# UPD70F3508 register map
Vendor: Renesas; Series: V850E2/Px4; File version: 1.0
CPU: other r0p0, little endian, no MPU, FPU, 4 interrupt priority bits
Registers are 8-bit, read-write, reset 0x0 unless marked. A register's access mark holds for its fields unless they carry their own. Offsets are from the block's base; [hi:lo] are bit positions; {n}, {i} and the like mark numbered series.

## FLX0 — FlexRay controller 0 (E-Ray)
Base 0xFF580000
0x00 FLX0CI 32-bit ro reset 0x65726179 — Controller information
  [31:0] FLX0MN — Controller information (ASCII eray)
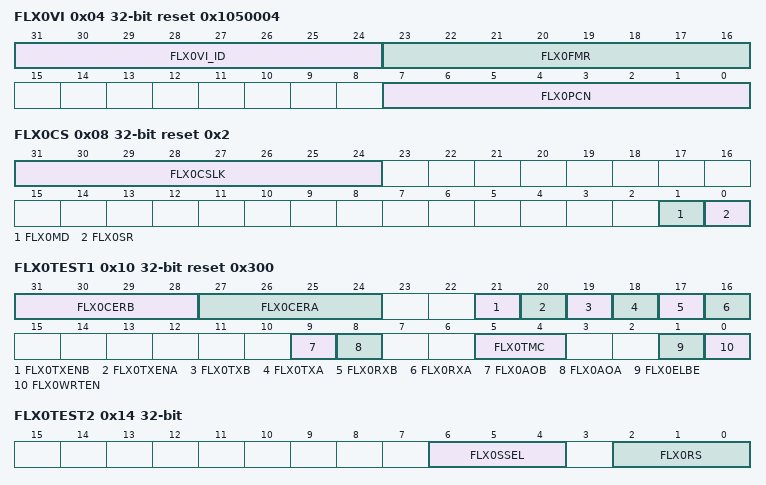
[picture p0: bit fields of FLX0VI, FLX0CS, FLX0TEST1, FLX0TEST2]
0x04 FLX0VI 32-bit ro reset 0x1050004 — Vendor information
  [31:24] FLX0VI_ID — Vendor ID
  [23:16] FLX0FMR — FlexRay controller release number
  [7:0] FLX0PCN — Product code number
0x08 FLX0CS 32-bit reset 0x2 — Control setting
  [31:24] FLX0CSLK — Control setting lock key
  [1] FLX0MD — Controller disable
  [0] FLX0SR — Software reset
0x10 FLX0TEST1 32-bit reset 0x300 — Test register 1
  [31:28] FLX0CERB — Coding error report channel B
  [27:24] FLX0CERA — Coding error report channel A
  [21] FLX0TXENB — Control of channel B transmit enable signal
  [20] FLX0TXENA — Control of channel A transmit enable signal
  [19] FLX0TXB — Control of channel B transmit signal
  [18] FLX0TXA — Control of channel A transmit signal
  [17] FLX0RXB — Monitor channel B receive signal
  [16] FLX0RXA — Monitor channel A receive signal
  [9] FLX0AOB — Activity detected on channel B
  [8] FLX0AOA — Activity detected on channel A
  [5:4] FLX0TMC — Test multiplexer control
  [1] FLX0ELBE — External loop back enable
  [0] FLX0WRTEN — Write test register enable
0x14 FLX0TEST2 32-bit — Test register 2
  [6:4] FLX0SSEL — RAM segment setting
  [2:0] FLX0RS — RAM selection setting
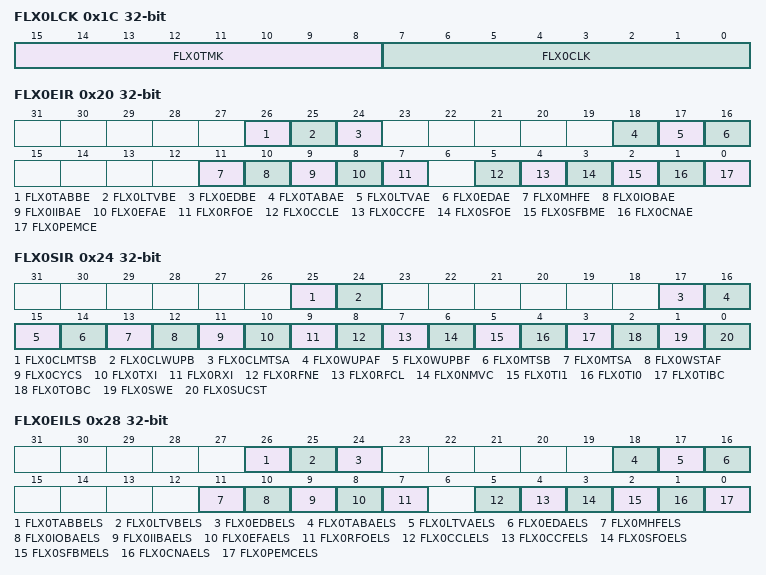
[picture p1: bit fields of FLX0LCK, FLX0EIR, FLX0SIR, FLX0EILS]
0x1C FLX0LCK 32-bit — Lock register
  [15:8] FLX0TMK — Test mode key
  [7:0] FLX0CLK — Configuration lock key
0x20 FLX0EIR 32-bit — Error interrupt register
  [26] FLX0TABBE — Transmission slot boundary violation on channel B
  [25] FLX0LTVBE — Latest transmit violation on channel B
  [24] FLX0EDBE — Error detected on channel B
  [18] FLX0TABAE — Transmission slot boundary violation on channel A
  [17] FLX0LTVAE — Latest transmit violation on channel A
  [16] FLX0EDAE — Error detected on channel A
  [11] FLX0MHFE — Message handler constraints flag
  [10] FLX0IOBAE — Illegal output buffer access
  [9] FLX0IIBAE — Illegal input buffer access
  [8] FLX0EFAE — Empty FIFO access
  [7] FLX0RFOE — Receive FIFO overrun
  [5] FLX0CCLE — CHI command locked
  [4] FLX0CCFE — Clock correction failure
  [3] FLX0SFOE — Sync frame overflow
  [2] FLX0SFBME — Sync frames below minimum
  [1] FLX0CNAE — Command not accepted
  [0] FLX0PEMCE — POC error mode changed
0x24 FLX0SIR 32-bit — Status interrupt register
  [25] FLX0CLMTSB — Clear MTS channel B
  [24] FLX0CLWUPB — Clear wakeup channel B
  [17] FLX0CLMTSA — Clear MTS channel A
  [16] FLX0WUPAF — Wakeup pattern received on channel A
  [15] FLX0WUPBF — Wakeup pattern received on channel B
  [14] FLX0MTSB — MTS received on channel B
  [13] FLX0MTSA — MTS received on channel A
  [12] FLX0WSTAF — Wakeup status changed flag
  [11] FLX0CYCS — Cycle start
  [10] FLX0TXI — Transmission interrupt
  [9] FLX0RXI — Receive interrupt
  [8] FLX0RFNE — Receive FIFO not empty
  [7] FLX0RFCL — Receive FIFO critical level
  [6] FLX0NMVC — Network management vector changed
  [5] FLX0TI1 — Timer interrupt 1
  [4] FLX0TI0 — Timer interrupt 0
  [3] FLX0TIBC — Transfer input buffer completed
  [2] FLX0TOBC — Transfer output buffer completed
  [1] FLX0SWE — Stop watch event
  [0] FLX0SUCST — Startup completed successfully
0x28 FLX0EILS 32-bit — Error interrupt line select
  [26] FLX0TABBELS — TABBE interrupt line select
  [25] FLX0LTVBELS — LTVBE interrupt line select
  [24] FLX0EDBELS — EDBE interrupt line select
  [18] FLX0TABAELS — TABAE interrupt line select
  [17] FLX0LTVAELS — LTVAE interrupt line select
  [16] FLX0EDAELS — EDAE interrupt line select
  [11] FLX0MHFELS — MHFE interrupt line select
  [10] FLX0IOBAELS — IOBAE interrupt line select
  [9] FLX0IIBAELS — IIBAE interrupt line select
  [8] FLX0EFAELS — EFAE interrupt line select
  [7] FLX0RFOELS — RFOE interrupt line select
  [5] FLX0CCLELS — CCLE interrupt line select
  [4] FLX0CCFELS — CCFE interrupt line select
  [3] FLX0SFOELS — SFOE interrupt line select
  [2] FLX0SFBMELS — SFBME interrupt line select
  [1] FLX0CNAELS — CNAE interrupt line select
  [0] FLX0PEMCELS — PEMCE interrupt line select
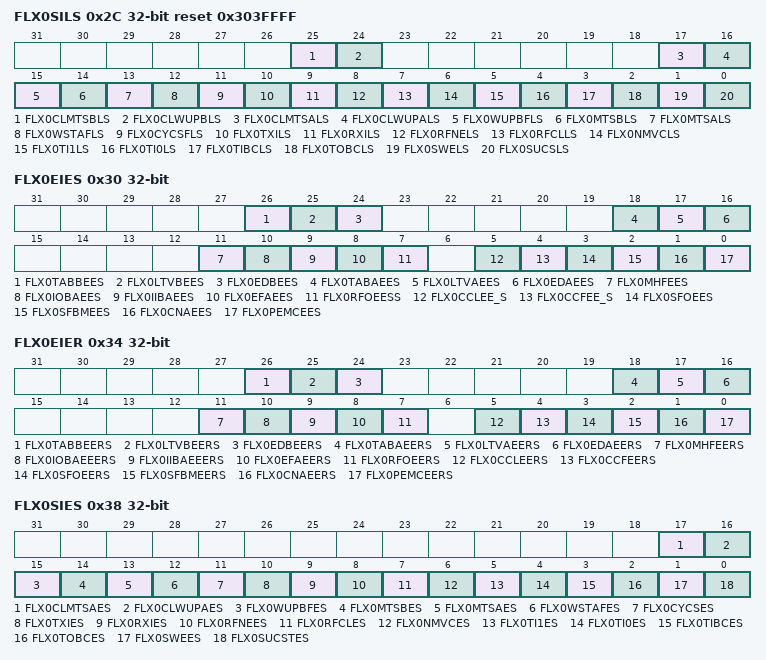
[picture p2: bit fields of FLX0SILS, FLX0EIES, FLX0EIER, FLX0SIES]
0x2C FLX0SILS 32-bit reset 0x303FFFF — Status interrupt line select
  [25] FLX0CLMTSBLS — CLMTSB line select
  [24] FLX0CLWUPBLS — CLWUPB line select
  [17] FLX0CLMTSALS — CLMTSA line select
  [16] FLX0CLWUPALS — CLWUPA line select
  [15] FLX0WUPBFLS — WUPBF line select
  [14] FLX0MTSBLS — MTSB line select
  [13] FLX0MTSALS — MTSA line select
  [12] FLX0WSTAFLS — WSTAF line select
  [11] FLX0CYCSFLS — CYCS line select
  [10] FLX0TXILS — TXI line select
  [9] FLX0RXILS — RXI line select
  [8] FLX0RFNELS — RFNE line select
  [7] FLX0RFCLLS — RFCL line select
  [6] FLX0NMVCLS — NMVC line select
  [5] FLX0TI1LS — TI1 line select
  [4] FLX0TI0LS — TI0 line select
  [3] FLX0TIBCLS — TIBC line select
  [2] FLX0TOBCLS — TOBC line select
  [1] FLX0SWELS — SWE line select
  [0] FLX0SUCSLS — SUCST line select
0x30 FLX0EIES 32-bit — Error interrupt enable set
  [26] FLX0TABBEES — TABBE enable set
  [25] FLX0LTVBEES — LTVBE enable set
  [24] FLX0EDBEES — EDBE enable set
  [18] FLX0TABAEES — TABAE enable set
  [17] FLX0LTVAEES — LTVAE enable set
  [16] FLX0EDAEES — EDAE enable set
  [11] FLX0MHFEES — MHFE enable set
  [10] FLX0IOBAEES — IOBAE enable set
  [9] FLX0IIBAEES — IIBAE enable set
  [8] FLX0EFAEES — EFAE enable set
  [7] FLX0RFOEESS — RFOE enable set
  [5] FLX0CCLEE_S — CCLE enable set
  [4] FLX0CCFEE_S — CCFE enable set
  [3] FLX0SFOEES — SFOE enable set
  [2] FLX0SFBMEES — SFBME enable set
  [1] FLX0CNAEES — CNAE enable set
  [0] FLX0PEMCEES — PEMCE enable set
0x34 FLX0EIER 32-bit — Error interrupt enable reset
  [26] FLX0TABBEERS — TABBE enable reset
  [25] FLX0LTVBEERS — LTVBE enable reset
  [24] FLX0EDBEERS — EDBE enable reset
  [18] FLX0TABAEERS — TABAE enable reset
  [17] FLX0LTVAEERS — LTVAE enable reset
  [16] FLX0EDAEERS — EDAE enable reset
  [11] FLX0MHFEERS — MHFE enable reset
  [10] FLX0IOBAEEERS — IOBAE enable reset
  [9] FLX0IIBAEEERS — IIBAE enable reset
  [8] FLX0EFAEERS — EFAE enable reset
  [7] FLX0RFOEERS — RFOE enable reset
  [5] FLX0CCLEERS — CCLE enable reset
  [4] FLX0CCFEERS — CCFE enable reset
  [3] FLX0SFOEERS — SFOE enable reset
  [2] FLX0SFBMEERS — SFBME enable reset
  [1] FLX0CNAEERS — CNAE enable reset
  [0] FLX0PEMCEERS — PEMCE enable reset
0x38 FLX0SIES 32-bit — Status interrupt enable set
  [17] FLX0CLMTSAES — CLMTSA enable set
  [16] FLX0CLWUPAES — CLWUPA enable set
  [15] FLX0WUPBFES — WUPBF enable set
  [14] FLX0MTSBES — MTSB enable set
  [13] FLX0MTSAES — MTSA enable set
  [12] FLX0WSTAFES — WSTAF enable set
  [11] FLX0CYCSES — CYCS enable set
  [10] FLX0TXIES — TXI enable set
  [9] FLX0RXIES — RXI enable set
  [8] FLX0RFNEES — RFNE enable set
  [7] FLX0RFCLES — RFCL enable set
  [6] FLX0NMVCES — NMVC enable set
  [5] FLX0TI1ES — TI1 enable set
  [4] FLX0TI0ES — TI0 enable set
  [3] FLX0TIBCES — TIBC enable set
  [2] FLX0TOBCES — TOBC enable set
  [1] FLX0SWEES — SWE enable set
  [0] FLX0SUCSTES — SUCST enable set
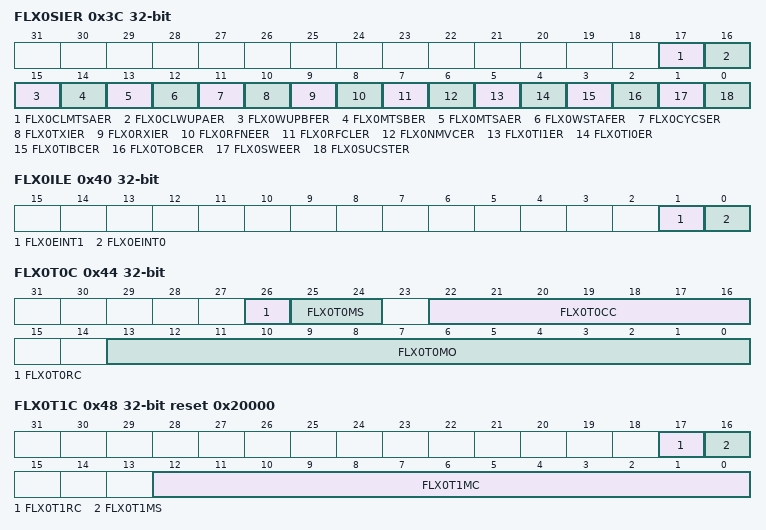
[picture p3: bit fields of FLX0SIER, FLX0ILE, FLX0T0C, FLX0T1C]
0x3C FLX0SIER 32-bit — Status interrupt enable reset
  [17] FLX0CLMTSAER — CLMTSA enable reset
  [16] FLX0CLWUPAER — CLWUPA enable reset
  [15] FLX0WUPBFER — WUPBF enable reset
  [14] FLX0MTSBER — MTSB enable reset
  [13] FLX0MTSAER — MTSA enable reset
  [12] FLX0WSTAFER — WSTAF enable reset
  [11] FLX0CYCSER — CYCS enable reset
  [10] FLX0TXIER — TXI enable reset
  [9] FLX0RXIER — RXI enable reset
  [8] FLX0RFNEER — RFNE enable reset
  [7] FLX0RFCLER — RFCL enable reset
  [6] FLX0NMVCER — NMVC enable reset
  [5] FLX0TI1ER — TI1 enable reset
  [4] FLX0TI0ER — TI0 enable reset
  [3] FLX0TIBCER — TIBC enable reset
  [2] FLX0TOBCER — TOBC enable reset
  [1] FLX0SWEER — SWE enable reset
  [0] FLX0SUCSTER — SUCST enable reset
0x40 FLX0ILE 32-bit — Interrupt line enable
  [1] FLX0EINT1 — Interrupt line 1 enable
  [0] FLX0EINT0 — Interrupt line 0 enable
0x44 FLX0T0C 32-bit — Timer 0 configuration
  [26] FLX0T0RC — Timer 0 repetition bit
  [25:24] FLX0T0MS — Timer 0 mode select
  [22:16] FLX0T0CC — Timer 0 cycle code
  [13:0] FLX0T0MO — Timer 0 macrotick offset
0x48 FLX0T1C 32-bit reset 0x20000 — Timer 1 configuration
  [17] FLX0T1RC — Timer 1 repetition bit
  [16] FLX0T1MS — Timer 1 mode select
  [12:0] FLX0T1MC — Timer 1 macrotick count
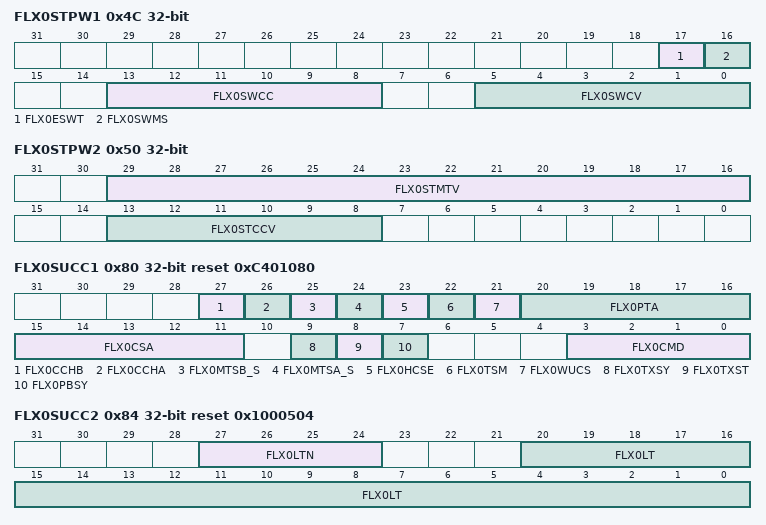
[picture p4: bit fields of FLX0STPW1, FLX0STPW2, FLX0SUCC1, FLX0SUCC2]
0x4C FLX0STPW1 32-bit — Stop watch register 1
  [17] FLX0ESWT — Enable stop watch trigger
  [16] FLX0SWMS — Stop watch mode select
  [13:8] FLX0SWCC — Stop watch cycle code
  [5:0] FLX0SWCV — Stop watch comparison value
0x50 FLX0STPW2 32-bit ro — Stop watch register 2
  [29:16] FLX0STMTV — Stop watch captured macrotick value
  [13:8] FLX0STCCV — Stop watch captured cycle counter value
0x80 FLX0SUCC1 32-bit reset 0xC401080 — SUC configuration register 1
  [27] FLX0CCHB — Connected to channel B
  [26] FLX0CCHA — Connected to channel A
  [25] FLX0MTSB_S — Select channel B for MTS transmission
  [24] FLX0MTSA_S — Select channel A for MTS transmission
  [23] FLX0HCSE — Halt due to clock sync error
  [22] FLX0TSM — Transmission slot mode
  [21] FLX0WUCS — Wakeup channel select
  [20:16] FLX0PTA — Passive to active
  [15:11] FLX0CSA — Cold start attempts
  [9] FLX0TXSY — Transmit sync frame in key slot
  [8] FLX0TXST — Transmit startup frame in key slot
  [7] FLX0PBSY — POC busy
  [3:0] FLX0CMD — CHI command vector
0x84 FLX0SUCC2 32-bit reset 0x1000504 — SUC configuration register 2
  [27:24] FLX0LTN — Listen timeout noise
  [20:0] FLX0LT — Listen timeout
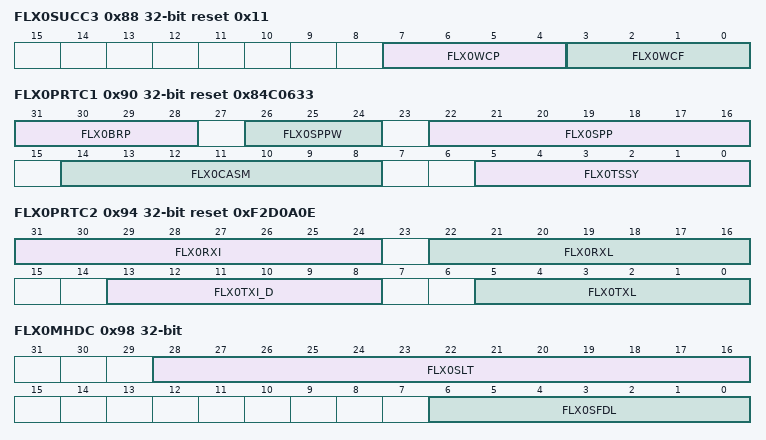
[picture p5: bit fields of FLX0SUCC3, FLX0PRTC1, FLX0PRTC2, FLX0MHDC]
0x88 FLX0SUCC3 32-bit reset 0x11 — SUC configuration register 3
  [7:4] FLX0WCP — Wakeup CAS pattern repetitions
  [3:0] FLX0WCF — Wakeup counter during first gap
0x8C FLX0NEMC 32-bit — NEM configuration register
  [3:0] FLX0NML — Network management vector length
0x90 FLX0PRTC1 32-bit reset 0x84C0633 — PRT configuration register 1
  [31:28] FLX0BRP — Baud rate prescaler
  [26:24] FLX0SPPW — Samples per bit window
  [22:16] FLX0SPP — Samples per bit
  [14:8] FLX0CASM — CAS/MTS symbol length
  [5:0] FLX0TSSY — Transmission start sequence length
0x94 FLX0PRTC2 32-bit reset 0xF2D0A0E — PRT configuration register 2
  [31:24] FLX0RXI — RX to idle delay
  [22:16] FLX0RXL — RX low idle delay
  [13:8] FLX0TXI_D — TX to idle delay
  [5:0] FLX0TXL — TX low idle delay
0x98 FLX0MHDC 32-bit — MHD configuration register
  [28:16] FLX0SLT — Static slot transmit buffer
  [6:0] FLX0SFDL — Static frame data length
0xA0 FLX0GTUC01 32-bit reset 0x280 — GTU configuration register 1
  [19:0] FLX0UT — Microtick per cycle
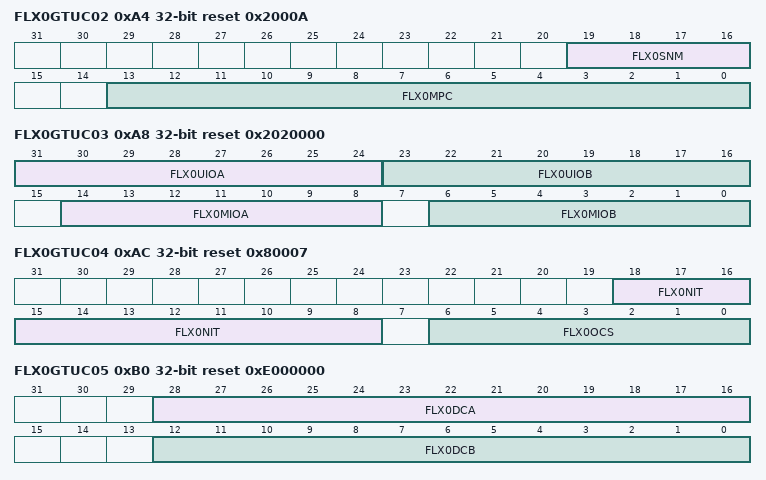
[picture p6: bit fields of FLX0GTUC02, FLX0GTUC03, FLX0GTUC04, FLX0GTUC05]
0xA4 FLX0GTUC02 32-bit reset 0x2000A — GTU configuration register 2
  [19:16] FLX0SNM — Sync node max
  [13:0] FLX0MPC — Macrotick per cycle
0xA8 FLX0GTUC03 32-bit reset 0x2020000 — GTU configuration register 3
  [31:24] FLX0UIOA — Microtick initial offset channel A
  [23:16] FLX0UIOB — Microtick initial offset channel B
  [14:8] FLX0MIOA — Macrotick initial offset channel A
  [6:0] FLX0MIOB — Macrotick initial offset channel B
0xAC FLX0GTUC04 32-bit reset 0x80007 — GTU configuration register 4
  [18:8] FLX0NIT — Network idle time start
  [6:0] FLX0OCS — Offset correction start
0xB0 FLX0GTUC05 32-bit reset 0xE000000 — GTU configuration register 5
  [28:16] FLX0DCA — Delay compensation channel A
  [12:0] FLX0DCB — Delay compensation channel B
0xB4 FLX0GTUC06 32-bit reset 0x20000 — GTU configuration register 6
  [19:0] FLX0ASR — Accepted startup range
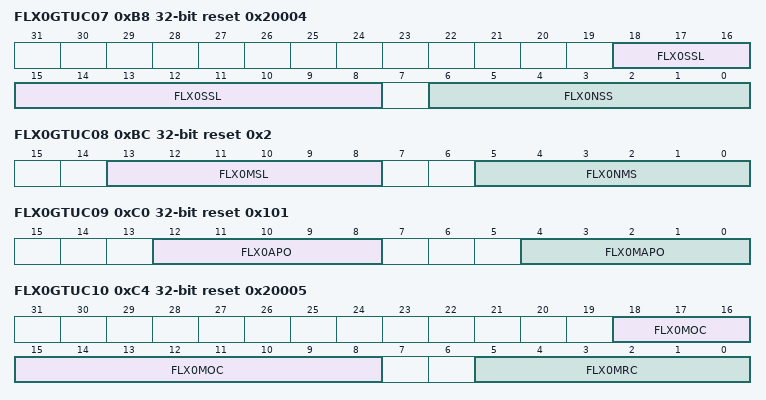
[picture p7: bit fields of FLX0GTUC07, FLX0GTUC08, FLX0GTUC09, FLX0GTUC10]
0xB8 FLX0GTUC07 32-bit reset 0x20004 — GTU configuration register 7
  [18:8] FLX0SSL — Static slot length
  [6:0] FLX0NSS — Number of static slots
0xBC FLX0GTUC08 32-bit reset 0x2 — GTU configuration register 8
  [13:8] FLX0MSL — Minislot length
  [5:0] FLX0NMS — Number of minislots
0xC0 FLX0GTUC09 32-bit reset 0x101 — GTU configuration register 9
  [12:8] FLX0APO — Action point offset
  [4:0] FLX0MAPO — Minislot action point offset
0xC4 FLX0GTUC10 32-bit reset 0x20005 — GTU configuration register 10
  [18:8] FLX0MOC — Maximum offset correction
  [5:0] FLX0MRC — Maximum rate correction
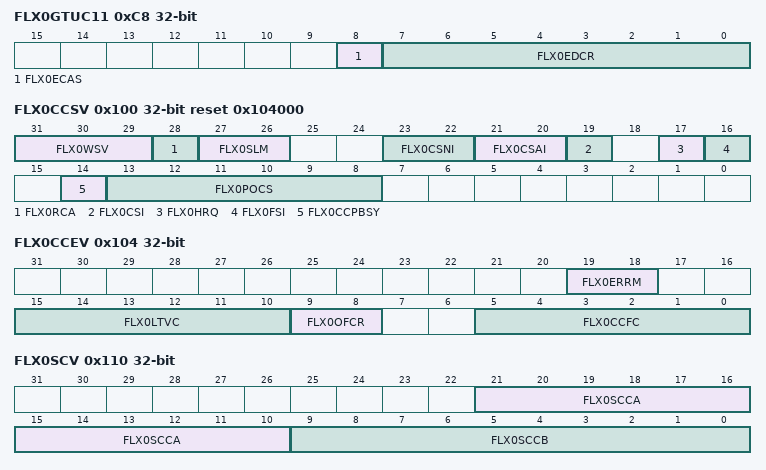
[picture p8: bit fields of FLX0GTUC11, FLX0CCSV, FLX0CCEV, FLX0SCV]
0xC8 FLX0GTUC11 32-bit — GTU configuration register 11
  [8] FLX0ECAS — External clock correction channel A select
  [7:0] FLX0EDCR — External delay correction
0x100 FLX0CCSV 32-bit ro reset 0x104000 — CC status vector
  [31:29] FLX0WSV — Wakeup status
  [28] FLX0RCA — Remaining cold start attempts
  [27:26] FLX0SLM — Slot mode
  [23:22] FLX0CSNI — Cold start noise indicator
  [21:20] FLX0CSAI — Cold start abort indicator
  [19] FLX0CSI — Cold start inhibit
  [17] FLX0HRQ — Halt request
  [16] FLX0FSI — Freeze status indicator
  [14] FLX0CCPBSY — POC busy
  [13:8] FLX0POCS — POC state
0x104 FLX0CCEV 32-bit ro — CC error vector
  [19:18] FLX0ERRM — Error mode
  [15:10] FLX0LTVC — Listen timeout violation counter
  [9:8] FLX0OFCR — Offset correction failed counter
  [5:0] FLX0CCFC — Clock correction failed counter
0x110 FLX0SCV 32-bit ro — Slot counter value
  [21:10] FLX0SCCA — Slot counter channel A
  [9:0] FLX0SCCB — Slot counter channel B
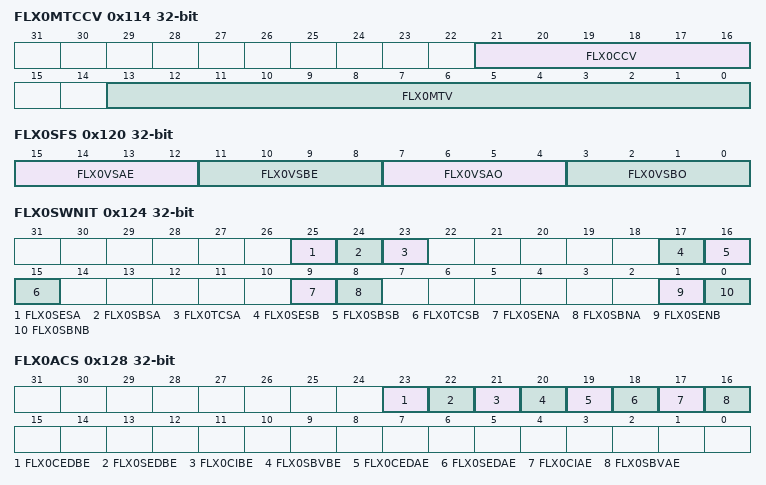
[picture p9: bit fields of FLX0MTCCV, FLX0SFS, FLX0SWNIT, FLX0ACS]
0x114 FLX0MTCCV 32-bit ro — Macrotick and cycle counter value
  [21:16] FLX0CCV — Cycle counter value
  [13:0] FLX0MTV — Macrotick value
0x118 FLX0RCV 32-bit ro — Rate correction value
  [10:0] FLX0RCVVAL
0x11C FLX0OCV 32-bit ro — Offset correction value
  [18:0] FLX0OCVVAL
0x120 FLX0SFS 32-bit ro — Sync frame status
  [15:12] FLX0VSAE — Valid sync frames even channel A
  [11:8] FLX0VSBE — Valid sync frames even channel B
  [7:4] FLX0VSAO — Valid sync frames odd channel A
  [3:0] FLX0VSBO — Valid sync frames odd channel B
0x124 FLX0SWNIT 32-bit ro — Symbol window and NIT status
  [25] FLX0SESA — Syntax error symbol window channel A
  [24] FLX0SBSA — Slot boundary violation symbol window channel A
  [23] FLX0TCSA — Transmission conflict symbol window channel A
  [17] FLX0SESB — Syntax error symbol window channel B
  [16] FLX0SBSB — Slot boundary violation symbol window channel B
  [15] FLX0TCSB — Transmission conflict symbol window channel B
  [9] FLX0SENA — Syntax error NIT channel A
  [8] FLX0SBNA — Slot boundary violation NIT channel A
  [1] FLX0SENB — Syntax error NIT channel B
  [0] FLX0SBNB — Slot boundary violation NIT channel B
0x128 FLX0ACS 32-bit — Aggregated channel status
  [23] FLX0CEDBE — Content error detected channel B even
  [22] FLX0SEDBE — Slot boundary violation channel B even
  [21] FLX0CIBE — Content error in boundary channel B
  [20] FLX0SBVBE — Slot boundary violation channel B
  [19] FLX0CEDAE — Content error detected channel A even
  [18] FLX0SEDAE — Slot boundary violation channel A even
  [17] FLX0CIAE — Content error in boundary channel A
  [16] FLX0SBVAE — Slot boundary violation channel A
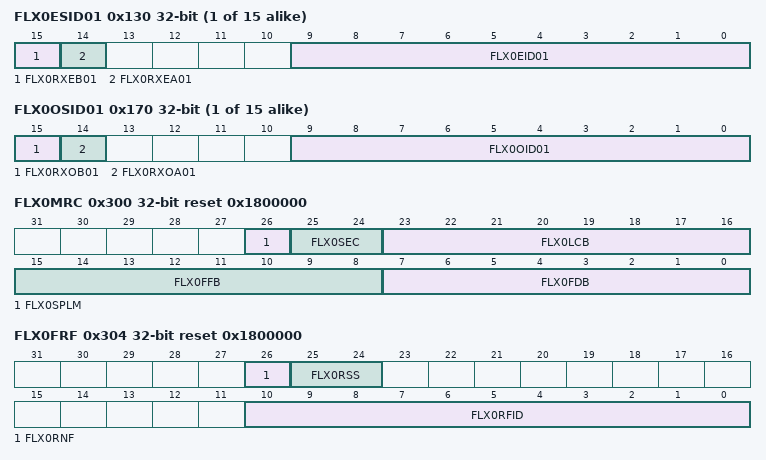
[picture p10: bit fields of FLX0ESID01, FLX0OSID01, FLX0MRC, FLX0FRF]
{0x12C+4i} FLX0ESID{i:02} 32-bit ro (i=1..15) — Even sync ID register {i:02}
  [15] FLX0RXEB{i:02} — Sync frame received on channel B
  [14] FLX0RXEA{i:02} — Sync frame received on channel A
  [9:0] FLX0EID{i:02} — Even sync ID
{0x16C+4i} FLX0OSID{i:02} 32-bit ro (i=1..15) — Odd sync ID register {i:02}
  [15] FLX0RXOB{i:02} — Sync frame received on channel B odd
  [14] FLX0RXOA{i:02} — Sync frame received on channel A odd
  [9:0] FLX0OID{i:02} — Odd sync ID
{0x1AC+4i} FLX0NMV{i} 32-bit ro (i=1..3) — Network management vector register {i}
  [31:0] FLX0NM{i}D — Network management vector data
0x300 FLX0MRC 32-bit reset 0x1800000 — Message RAM configuration
  [26] FLX0SPLM — Single payload limit mode
  [25:24] FLX0SEC — Static frame ID rejection
  [23:16] FLX0LCB — Last configured buffer
  [15:8] FLX0FFB — First FIFO buffer
  [7:0] FLX0FDB — First dynamic buffer
0x304 FLX0FRF 32-bit reset 0x1800000 — FIFO rejection filter
  [26] FLX0RNF — Reject null frames
  [25:24] FLX0RSS — Reject sync segment frames
  [10:0] FLX0RFID — Receive FIFO frame ID rejection
0x308 FLX0FRFM 32-bit — FIFO rejection filter mask
  [10:0] FLX0RFIDM — FIFO frame ID rejection mask
0x30C FLX0FCL 32-bit reset 0x80 — FIFO critical level
  [7:0] FLX0CL
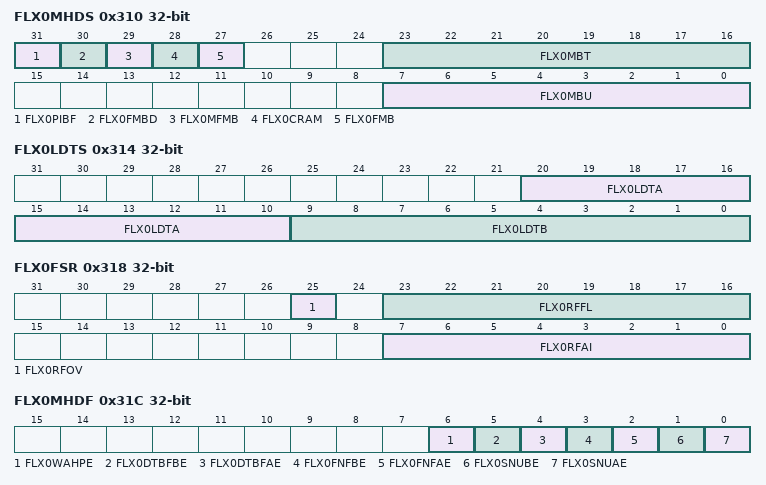
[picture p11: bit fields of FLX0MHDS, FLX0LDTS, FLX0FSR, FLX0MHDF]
0x310 FLX0MHDS 32-bit — Message handler status
  [31] FLX0PIBF — Payload input buffer full
  [30] FLX0FMBD — Faulty message buffer detected
  [29] FLX0MFMB — Maximum FIFO message buffer
  [28] FLX0CRAM — Clear RAM active
  [27] FLX0FMB — Faulty message buffer
  [23:16] FLX0MBT — Message buffer transmit
  [7:0] FLX0MBU — Message buffer update
0x314 FLX0LDTS 32-bit ro — Last dynamic transmit slot
  [20:10] FLX0LDTA — Last dynamic transmit slot channel A
  [9:0] FLX0LDTB — Last dynamic transmit slot channel B
0x318 FLX0FSR 32-bit ro — FIFO status register
  [25] FLX0RFOV — Receive FIFO overrun
  [23:16] FLX0RFFL — Receive FIFO fill level
  [7:0] FLX0RFAI — Receive FIFO access index
0x31C FLX0MHDF 32-bit — Message handler constraints flags
  [6] FLX0WAHPE — Write access to header partition error
  [5] FLX0DTBFBE — Data transmit buffer full error channel B
  [4] FLX0DTBFAE — Data transmit buffer full error channel A
  [3] FLX0FNFBE — FIFO not free channel B error
  [2] FLX0FNFAE — FIFO not free channel A error
  [1] FLX0SNUBE — Sync node undefined error channel B
  [0] FLX0SNUAE — Sync node undefined error channel A
{0x31C+4i} FLX0TXRQ{i} 32-bit ro (i=1..4) — Transmission request {i}
  [31:0] FLX0TXR{32i-1:03} — Transmission request bits {32i-1:03}:{32i-32:03}
{0x32C+4i} FLX0NDAT{i} 32-bit ro (i=1..4) — New data {i}
  [31:0] FLX0ND{32i-1:03} — New data bits {32i-1:03}:{32i-32:03}
{0x33C+4i} FLX0MBSC{i} 32-bit ro (i=1..4) — Message buffer status changed {i}
  [31:0] FLX0MBC{32i-1:03} — Message buffer status changed bits {32i-1:03}:{32i-32:03}
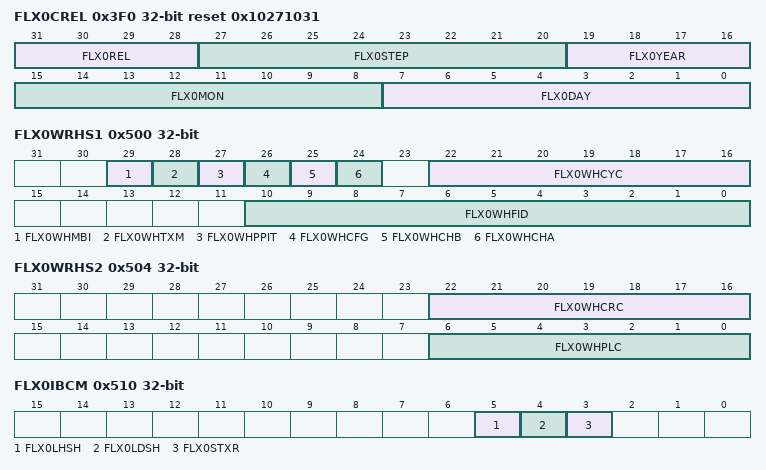
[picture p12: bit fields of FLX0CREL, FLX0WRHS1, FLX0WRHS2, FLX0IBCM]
0x3F0 FLX0CREL 32-bit ro reset 0x10271031 — Core release register
  [31:28] FLX0REL — Core release
  [27:20] FLX0STEP — Core step
  [19:16] FLX0YEAR — Core release year
  [15:8] FLX0MON — Core release month
  [7:0] FLX0DAY — Core release day
0x3F4 FLX0ENDN 32-bit ro reset 0x87654321 — Endian register
  [31:0] FLX0ETV — Endian test value
{0x3FC+4i} FLX0WRDS{i:02} 32-bit (i=1..64) — Write data section register {i:02}
  [31:0] FLX0DW{i:02} — Data word
0x500 FLX0WRHS1 32-bit — Write header section 1
  [29] FLX0WHMBI — Message buffer interrupt enable
  [28] FLX0WHTXM — Transmission mode
  [27] FLX0WHPPIT — Payload preamble indicator transmit
  [26] FLX0WHCFG — Buffer direction TX/RX
  [25] FLX0WHCHB — Channel B assignment
  [24] FLX0WHCHA — Channel A assignment
  [22:16] FLX0WHCYC — Cycle counter filter
  [10:0] FLX0WHFID — Frame ID
0x504 FLX0WRHS2 32-bit — Write header section 2
  [22:16] FLX0WHCRC — Header CRC
  [6:0] FLX0WHPLC — Payload length configured
0x508 FLX0WRHS3 32-bit — Write header section 3
  [6:0] FLX0WHDP — Data pointer
0x510 FLX0IBCM 32-bit — Input buffer command mask
  [5] FLX0LHSH — Write header section to IBF
  [4] FLX0LDSH — Write data section to IBF
  [3] FLX0STXR — Set transmission request
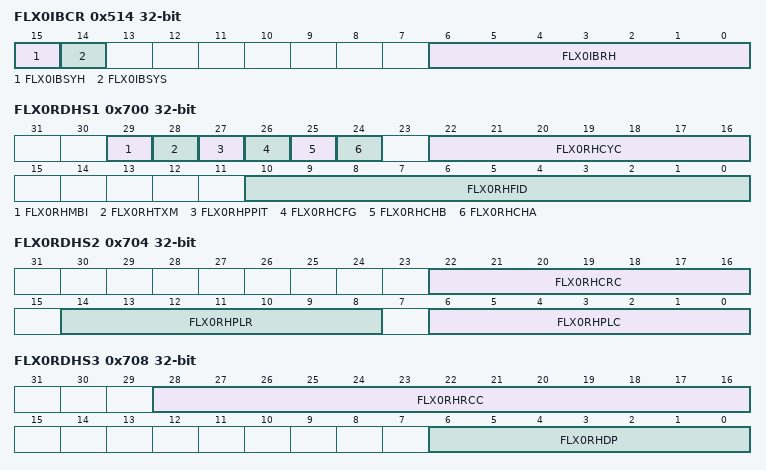
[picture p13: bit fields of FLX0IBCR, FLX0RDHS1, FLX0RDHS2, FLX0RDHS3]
0x514 FLX0IBCR 32-bit — Input buffer command request
  [15] FLX0IBSYH — Input buffer host busy
  [14] FLX0IBSYS — Input buffer shadow busy
  [6:0] FLX0IBRH — Input buffer request host side
{0x5FC+4i} FLX0RDDS{i:02} 32-bit ro (i=1..64) — Read data section register {i:02}
  [31:0] FLX0RDW{i:02} — Read data word
0x700 FLX0RDHS1 32-bit ro — Read header section 1
  [29] FLX0RHMBI — Message buffer interrupt
  [28] FLX0RHTXM — Transmission mode
  [27] FLX0RHPPIT — Payload preamble indicator
  [26] FLX0RHCFG — Buffer direction
  [25] FLX0RHCHB — Channel B assignment
  [24] FLX0RHCHA — Channel A assignment
  [22:16] FLX0RHCYC — Cycle counter filter
  [10:0] FLX0RHFID — Frame ID
0x704 FLX0RDHS2 32-bit ro — Read header section 2
  [22:16] FLX0RHCRC — Header CRC
  [14:8] FLX0RHPLR — Payload length received
  [6:0] FLX0RHPLC — Payload length configured
0x708 FLX0RDHS3 32-bit ro — Read header section 3
  [28:16] FLX0RHRCC — Receive cycle count
  [6:0] FLX0RHDP — Data pointer
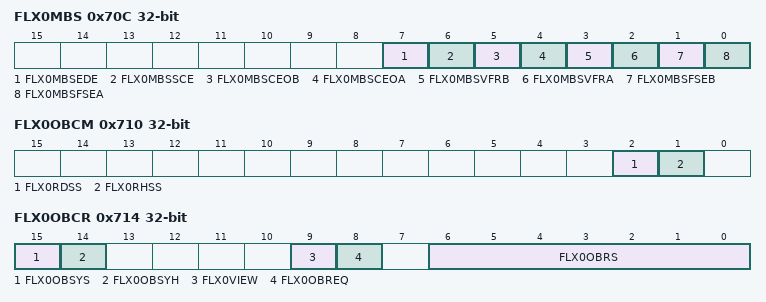
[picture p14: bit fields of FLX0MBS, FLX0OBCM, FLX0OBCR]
0x70C FLX0MBS 32-bit ro — Message buffer status
  [7] FLX0MBSEDE — ECC double error detected
  [6] FLX0MBSSCE — Single cycle error
  [5] FLX0MBSCEOB — Content error odd channel B
  [4] FLX0MBSCEOA — Content error odd channel A
  [3] FLX0MBSVFRB — Valid frame received channel B
  [2] FLX0MBSVFRA — Valid frame received channel A
  [1] FLX0MBSFSEB — Frame start error B
  [0] FLX0MBSFSEA — Frame start error A
0x710 FLX0OBCM 32-bit — Output buffer command mask
  [2] FLX0RDSS — Read data section from OBF
  [1] FLX0RHSS — Read header section from OBF
0x714 FLX0OBCR 32-bit — Output buffer command request
  [15] FLX0OBSYS — Output buffer shadow busy
  [14] FLX0OBSYH — Output buffer host busy
  [9] FLX0VIEW — Select view
  [8] FLX0OBREQ — Transfer request
  [6:0] FLX0OBRS — Output buffer request shadow
